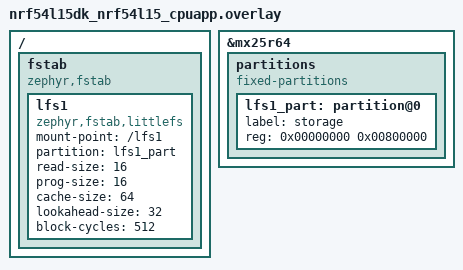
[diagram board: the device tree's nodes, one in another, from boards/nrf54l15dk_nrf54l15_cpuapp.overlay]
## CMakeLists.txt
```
cmake_minimum_required(VERSION 3.20.0)

list(APPEND ZEPHYR_EXTRA_MODULES ${CMAKE_CURRENT_SOURCE_DIR}/../lib)

find_package(Zephyr REQUIRED HINTS ../zephyr)
project(nrf54l15_cpp_app LANGUAGES C CXX)

# Disable exceptions and RTTI for embedded/ETL usage
add_compile_options(-fno-exceptions -fno-rtti)
zephyr_cc_option(-Wfatal-errors)
add_compile_options(-Wno-vla-cxx-extension)

target_sources(app PRIVATE src/main.cpp)

zephyr_include_directories(${ZEPHYR_BASE}/../etl/include)
```

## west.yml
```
manifest:

  remotes:
    - name: zephyrproject-rtos
      url-base: https://github.com/zephyrproject-rtos
    - name: etl
      url-base: https://github.com/ETLCPP

  projects:
    - name: zephyr
      remote: zephyrproject-rtos
      repo-path: zephyr
      revision: main
      clone-depth: 1
      import:
        name-allowlist:
          - cmsis_6
          - hal_nordic
          - littlefs
          - mbedtls
          - nrf_hw_models
          - segger

    - name: etl
      remote: etl
      revision: 20.44.1
      clone-depth: 1

  self:
    path: app
```

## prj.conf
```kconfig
# C++ support
CONFIG_CPP=y
CONFIG_STD_CPP23=y
CONFIG_REQUIRES_FULL_LIBCPP=y
CONFIG_FS_CPP=y

# Console
CONFIG_CONSOLE=y
CONFIG_RTT_CONSOLE=y
CONFIG_USE_SEGGER_RTT=y

CONFIG_SHELL=y
CONFIG_SHELL_BACKEND_RTT=y
CONFIG_SHELL_BACKEND_SERIAL=n
CONFIG_LOG_BACKEND_RTT_BUFFER=1

CONFIG_SHELL_TAB=y
CONFIG_SHELL_TAB_AUTOCOMPLETION=y

# Logging
CONFIG_LOG=y
CONFIG_LOG_BACKEND_RTT=y
CONFIG_LOG_DEFAULT_LEVEL=3

# GPIO (for future use with LEDs/buttons on the DK)
CONFIG_GPIO=y

CONFIG_I2C=y
CONFIG_I2C_SHELL=y

CONFIG_FLASH=y
CONFIG_FLASH_MAP=y

CONFIG_SPI=y
CONFIG_SPI_NOR=y
CONFIG_SPI_NOR_FLASH_LAYOUT_PAGE_SIZE=4096

CONFIG_FILE_SYSTEM=y
CONFIG_FILE_SYSTEM_LITTLEFS=y

# fs_dirent structures are big.
CONFIG_MAIN_STACK_SIZE=4096
```

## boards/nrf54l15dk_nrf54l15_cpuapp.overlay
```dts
/delete-node/ &storage_partition;

/ {
	fstab {
		compatible = "zephyr,fstab";

		lfs1: lfs1 {
			compatible = "zephyr,fstab,littlefs";
			mount-point = "/lfs1";
			partition = <&lfs1_part>;
			read-size = <16>;
			prog-size = <16>;
			cache-size = <64>;
			lookahead-size = <32>;
			block-cycles = <512>;
		};
	};
};

&mx25r64 {
	partitions {
		compatible = "fixed-partitions";
		#address-cells = <1>;
		#size-cells = <1>;

		lfs1_part: partition@0 {
			label = "storage";
			reg = <0x00000000 0x00800000>;
		};
	};
};
```

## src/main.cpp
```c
#include <zephyr/kernel.h>
#include <zephyr/logging/log.h>
#include <app/lib/fs.hpp>
#include <etl/span.h>
LOG_MODULE_REGISTER(main, CONFIG_LOG_DEFAULT_LEVEL);

#define PARTITION_NODE DT_NODELABEL(lfs1)

FS_FSTAB_DECLARE_ENTRY(PARTITION_NODE);
static fs_mount_t *s_mp = &FS_FSTAB_ENTRY(PARTITION_NODE);

static void print_stats(fs::Filesystem &fs)
{
	auto sv = fs.statvfs();
	if (!sv) {
		LOG_ERR("statvfs: %s", sv.error().what());
		return;
	}
	LOG_PRINTK("  blocks: %lu total, %lu free (%lu byte blocks)\n", sv->blocks, sv->blocks_free,
		   sv->block_size);
}

int main()
{
	auto fs_res = fs::Filesystem::mount(s_mp);
	if (!fs_res) {
		LOG_ERR("mount: %s", fs_res.error().what());
		return 0;
	}
	auto &fs = *fs_res;

	LOG_PRINTK("=== stats before write ===\n");
	print_stats(fs);
	{
		auto f = fs.open_file("hello.txt", fs::Filesystem::OpenFlags::CreateRW);
		if (!f) {
			LOG_ERR("open: %s", f.error().what());
			return 0;
		}

		const char *msg = "Hello Zephyr!";
		auto wr = f->write(etl::span<const uint8_t>(reinterpret_cast<const uint8_t *>(msg),
							    strlen(msg)));
		if (!wr) {
			LOG_ERR("write: %s", wr.error().what());
			return 0;
		}
		LOG_PRINTK("written %zu bytes\n", *wr);
		f->sync();
	}
	LOG_PRINTK("=== stats after write ===\n");
	print_stats(fs);
	{
		auto f = fs.open_file("hello.txt", fs::Filesystem::OpenFlags::ReadOnly);
		if (!f) {
			LOG_ERR("open: %s", f.error().what());
			return 0;
		}

		uint8_t buf[64] = {};
		auto rd = f->read(etl::span<uint8_t>(buf, sizeof(buf)));
		if (!rd) {
			LOG_ERR("read: %s", rd.error().what());
			return 0;
		}

		buf[*rd] = '\0';
		LOG_PRINTK("read back (%zu bytes): %s\n", *rd, reinterpret_cast<const char *>(buf));
	}
	while (true) {
		k_sleep(K_MSEC(1000));
	}
	return 0;
}
```
